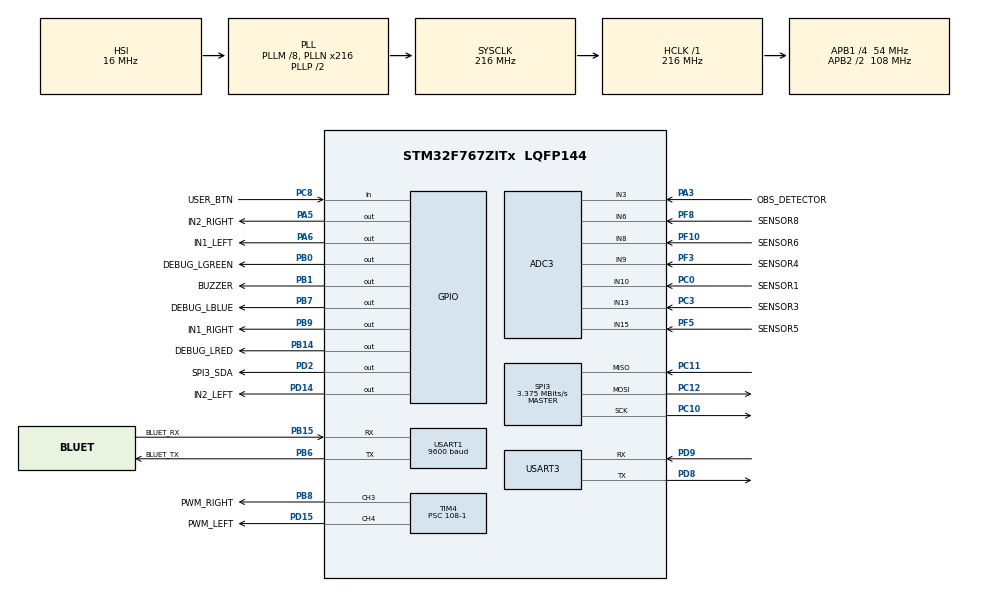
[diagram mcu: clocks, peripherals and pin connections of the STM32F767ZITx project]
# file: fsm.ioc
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Mcu.Family=STM32F7
NVIC.USART3_IRQn=true\:0\:0\:false\:false\:true\:true\:true
Dma.ADC3.0.FIFOMode=DMA_FIFOMODE_DISABLE
ADC2.ExternalTrigConv=ADC_SOFTWARE_START
Dma.ADC3.0.Priority=DMA_PRIORITY_LOW
RCC.CortexFreq_Value=216000000
SPI3.Direction=SPI_DIRECTION_2LINES
SPI3.VirtualType=VM_MASTER
ADC2.Channel-0\#ChannelRegularConversion=ADC_CHANNEL_3
ADC3.Channel-3\#ChannelRegularConversion=ADC_CHANNEL_15
NVIC.TIM6_DAC_IRQn=true\:0\:0\:true\:false\:true\:true\:true
USART1.BaudRate=9600
SPI3.NSSPMode=SPI_NSS_PULSE_DISABLE
PC10.Signal=SPI3_SCK
PC12.Signal=SPI3_MOSI
PB14.GPIO_Label=DEBUG_LRED
PC0.GPIO_Label=SENSOR1
PB0.GPIO_Label=DEBUG_LGREEN
PA6.GPIO_Label=IN1_LEFT
PB6.GPIO_Label=BLUET_TX
PB15.Signal=USART1_RX
ADC3.Channel-0\#ChannelRegularConversion=ADC_CHANNEL_10
PD9.Mode=Asynchronous
ADC3.Rank-2\#ChannelRegularConversion=3
RCC.SYSCLKSource=RCC_SYSCLKSOURCE_PLLCLK
ProjectManager.StackSize=0x400
USART3.VirtualMode-Asynchronous=VM_ASYNC
VP_TIM7_VS_ClockSourceINT.Mode=Enable_Timer
ADC3.SamplingTime-4\#ChannelRegularConversion=ADC_SAMPLETIME_112CYCLES
NVIC.ADC_IRQn=true\:0\:0\:false\:false\:true\:true\:true
ADC2.DMAContinuousRequests=ENABLE
RCC.HCLKFreq_Value=216000000
SH.ADCx_IN3.0=ADC3_IN3,IN3
SH.ADCx_IN3.1=ADC2_IN3,IN3
RCC.APB2TimFreq_Value=216000000
TIM3.Period=1800-1
PB6.Signal=USART1_TX
Dma.ADC3.0.Direction=DMA_PERIPH_TO_MEMORY
PB6.Mode=Asynchronous
PC3.Signal=ADCx_IN13
ADC3.ScanConvMode=ADC_SCAN_ENABLE
TIM7.Period=500-1
PD8.Signal=USART3_TX
Dma.ADC3.0.MemDataAlignment=DMA_MDATAALIGN_WORD
ADC2.EOCSelection=ADC_EOC_SINGLE_CONV
PF10.GPIO_Label=SENSOR6
RCC.AHBFreq_Value=216000000
SPI3.DataSize=SPI_DATASIZE_8BIT
TIM3.ClockDivision=TIM_CLOCKDIVISION_DIV1
ADC3.SamplingTime-1\#ChannelRegularConversion=ADC_SAMPLETIME_112CYCLES
RCC.HSE_VALUE=25000000
TIM4.Channel-PWM\ Generation3\ CH3=TIM_CHANNEL_3
ADC3.SamplingTime-2\#ChannelRegularConversion=ADC_SAMPLETIME_3CYCLES
Dma.ADC3.0.PeriphInc=DMA_PINC_DISABLE
Dma.ADC2.1.Instance=DMA2_Stream2
ADC3.SamplingTime-5\#ChannelRegularConversion=ADC_SAMPLETIME_112CYCLES
TIM3.Prescaler=60000-1
PB1.GPIO_Label=BUZZER
ADC3.ContinuousConvMode=ENABLE
Dma.ADC3.0.MemInc=DMA_MINC_ENABLE
PB7.Signal=GPIO_Output
PF8.Mode=IN6
Dma.ADC2.1.PeriphInc=DMA_PINC_DISABLE
TIM4.Period=100-0
TIM6.Period=100-1
ADC3.Channel-2\#ChannelRegularConversion=ADC_CHANNEL_9
PF3.Signal=ADC3_IN9
TIM7.TIM_MasterOutputTrigger=TIM_TRGO_UPDATE
ADC3.Rank-4\#ChannelRegularConversion=5
PB7.GPIO_Label=DEBUG_LBLUE
Mcu.Package=LQFP144
PB9.Signal=GPIO_Output
PB1.Signal=GPIO_Output
PA6.Signal=GPIO_Output
SPI3.Mode=SPI_MODE_MASTER
PF5.GPIO_Label=SENSOR5
ADC3.Rank-0\#ChannelRegularConversion=1
PF8.Signal=ADC3_IN6
ADC2.SamplingTime-0\#ChannelRegularConversion=ADC_SAMPLETIME_112CYCLES
TIM7.AutoReloadPreload=TIM_AUTORELOAD_PRELOAD_ENABLE
PC11.Mode=Full_Duplex_Master
NVIC.SPI3_IRQn=true\:0\:0\:false\:false\:true\:true\:true
PF5.Signal=ADC3_IN15
ADC3.DMAContinuousRequests=ENABLE
RCC.APB2CLKDivider=RCC_HCLK_DIV2
NVIC.DMA2_Stream2_IRQn=true\:0\:0\:false\:false\:true\:false\:true
Dma.Request1=ADC2
RCC.APB1TimFreq_Value=108000000
Dma.ADC3.0.Instance=DMA2_Stream1
PF10.Mode=IN8
ADC2.Rank-0\#ChannelRegularConversion=1
NVIC.USART1_IRQn=true\:0\:0\:false\:false\:true\:true\:true
TIM4.Channel-PWM\ Generation4\ CH4=TIM_CHANNEL_4
Dma.Request0=ADC3
PF3.GPIO_Label=SENSOR4
PD15.Signal=S_TIM4_CH4
Dma.ADC2.1.PeriphDataAlignment=DMA_PDATAALIGN_WORD
NVIC.TIM7_IRQn=true\:0\:0\:false\:false\:true\:true\:true
VP_TIM3_VS_ClockSourceINT.Mode=Internal
ADC2.ScanConvMode=ADC_SCAN_ENABLE
PA3.Signal=ADCx_IN3
ADC3.SamplingTime-3\#ChannelRegularConversion=ADC_SAMPLETIME_3CYCLES
SH.ADCx_IN13.0=ADC3_IN13,IN13
TIM4.AutoReloadPreload=TIM_AUTORELOAD_PRELOAD_ENABLE
PD15.GPIO_Label=PWM_LEFT
PF3.Mode=IN9
PB9.GPIO_Label=IN1_RIGHT
TIM3.AutoReloadPreload=TIM_AUTORELOAD_PRELOAD_ENABLE
SH.S_TIM4_CH4.0=TIM4_CH4,PWM Generation4 CH4
PC11.Signal=SPI3_MISO
PC8.Signal=GPIO_Input
TIM6.Prescaler=10800-1
PC10.Mode=Full_Duplex_Master
VP_TIM6_VS_ClockSourceINT.Mode=Enable_Timer
PD9.Signal=USART3_RX
NVIC.DMA2_Stream1_IRQn=true\:0\:0\:false\:false\:true\:false\:true
PC0.Signal=ADCx_IN10
ADC3.Rank-3\#ChannelRegularConversion=4
RCC.APB1CLKDivider=RCC_HCLK_DIV4
PF5.Mode=IN15
PF8.GPIO_Label=SENSOR8
PC8.GPIO_Label=USER_BTN
USART1.VirtualMode-Asynchronous=VM_ASYNC
TIM6.AutoReloadPreload=TIM_AUTORELOAD_PRELOAD_ENABLE
PB8.GPIO_Label=PWM_RIGHT
ADC3.SamplingTime-0\#ChannelRegularConversion=ADC_SAMPLETIME_112CYCLES
ADC2.ContinuousConvMode=ENABLE
ProjectManager.TargetToolchain=STM32CubeIDE
ADC3.Channel-4\#ChannelRegularConversion=ADC_CHANNEL_8
SH.S_TIM4_CH3.0=TIM4_CH3,PWM Generation3 CH3
RCC.USBFreq_Value=216000000
ADC3.NbrOfConversion=6
TIM4.Prescaler=108-1
Dma.ADC2.1.Mode=DMA_CIRCULAR
RCC.LSE_VALUE=32768
PD8.Mode=Asynchronous
PB14.Signal=GPIO_Output
PA5.Signal=GPIO_Output
Dma.ADC2.1.FIFOMode=DMA_FIFOMODE_DISABLE
PC12.Mode=Full_Duplex_Master
TIM7.Prescaler=10800-1
board=custom
RCC.VCOOutputFreq_Value=432000000
PB15.Mode=Asynchronous
NVIC.TIM3_IRQn=true\:0\:0\:false\:false\:true\:true\:true
RCC.APB2Freq_Value=108000000
ADC3.Channel-5\#ChannelRegularConversion=ADC_CHANNEL_6
SPI3.CalculateBaudRate=3.375 MBits/s
PB15.GPIO_Label=BLUET_RX
PF10.Signal=ADC3_IN8
SPI3.BaudRatePrescaler=SPI_BAUDRATEPRESCALER_16
TIM6.TIM_MasterOutputTrigger=TIM_TRGO_UPDATE
PD14.GPIO_Label=IN2_LEFT
Dma.ADC2.1.MemInc=DMA_MINC_ENABLE
ADC3.Rank-5\#ChannelRegularConversion=6
Mcu.Name=STM32F767ZITx
Dma.ADC3.0.PeriphDataAlignment=DMA_PDATAALIGN_WORD
ADC3.Channel-1\#ChannelRegularConversion=ADC_CHANNEL_13
PD14.Signal=GPIO_Output
PC8.GPIO_PuPd=GPIO_PULLDOWN
ADC3.Rank-1\#ChannelRegularConversion=2
RCC.SYSCLKFreq_VALUE=216000000
Dma.ADC2.1.Direction=DMA_PERIPH_TO_MEMORY
PA5.GPIO_Label=IN2_RIGHT
ADC2.NbrOfConversionFlag=1
SH.ADCx_IN10.1=ADC3_IN10,IN10
SH.ADCx_IN10.0=ADC1_IN10
ProjectManager.HeapSize=0x200
ADC3.EOCSelection=ADC_EOC_SINGLE_CONV
Dma.ADC3.0.Mode=DMA_CIRCULAR
RCC.HSI_VALUE=16000000
NVIC.PriorityGroup=NVIC_PRIORITYGROUP_4
Dma.ADC2.1.MemDataAlignment=DMA_MDATAALIGN_WORD
RCC.PLLM=8
RCC.PLLN=216
PB8.Signal=S_TIM4_CH3
PC3.GPIO_Label=SENSOR3
Dma.ADC2.1.Priority=DMA_PRIORITY_LOW
TIM3.TIM_MasterOutputTrigger=TIM_TRGO_UPDATE
PD2.Signal=GPIO_Output
NVIC.TIM4_IRQn=true\:0\:0\:false\:false\:true\:true\:true
RCC.APB1Freq_Value=54000000
ADC3.NbrOfConversionFlag=1
PB0.Signal=GPIO_Output
PD2.GPIO_Label=SPI3_SDA
PA3.GPIO_Label=OBS_DETECTOR

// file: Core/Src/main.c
/* USER CODE BEGIN Header */
/**
  ******************************************************************************
  * @file           : main.c
  * @brief          : Main program body
  ******************************************************************************
  * @attention
  *
  * <h2><center>&copy; Copyright (c) 2021 STMicroelectronics.
  * All rights reserved.</center></h2>
  *
  * This software component is licensed by ST under BSD 3-Clause license,
  * the "License"; You may not use this file except in compliance with the
  * License. You may obtain a copy of the License at:
  *                        opensource.org/licenses/BSD-3-Clause
  *
  ******************************************************************************
  */
/* USER CODE END Header */
#include "main.h"
#include "adc.h"
#include "dma.h"
#include "spi.h"
#include "tim.h"
#include "usart.h"
#include "gpio.h"

/* USER CODE BEGIN Includes */
#include "fsm.h"
#include "tests.h"

#include "rfid-rc522.h"
#include "timeout.h"
/* USER CODE END Includes */

void SystemClock_Config(void);

int main(void)
{

  /* MCU Configuration--------------------------------------------------------*/

  /* Reset of all peripherals, Initializes the Flash interface and the Systick. */
  HAL_Init();

  /* Configure the system clock */
  SystemClock_Config();

  /* Initialize all configured peripherals */
  MX_GPIO_Init();
  MX_DMA_Init();
  MX_SPI3_Init();
  MX_USART3_UART_Init();
  MX_TIM6_Init();
  MX_ADC3_Init();
  MX_TIM4_Init();
  MX_USART1_UART_Init();
  MX_TIM3_Init();
  MX_ADC2_Init();
  MX_TIM7_Init();

  /* Infinite loop */
  /* USER CODE BEGIN WHILE */

  // initialize FSM state and next state
  state = S_STOPPED;
  nstate = S_STOPPED;

  //while(1)
//	  test_lf_print_qtr();

  // enable RFID reader
  RFID_RC522_Init();
  // enable UART
  Rx_UART_init(&bluet_uart);
  // enable timeouts
  timeout_start();

  while (1)
  {
	  // execute state
	  fsm_func_ptr[state]();
	  // update current state
	  state = nstate;

    /* USER CODE END WHILE */

  }
}

void SystemClock_Config(void)
{
  RCC_OscInitTypeDef RCC_OscInitStruct = {0};
  RCC_ClkInitTypeDef RCC_ClkInitStruct = {0};
  RCC_PeriphCLKInitTypeDef PeriphClkInitStruct = {0};

  /** Configure the main internal regulator output voltage
  */
  __HAL_RCC_PWR_CLK_ENABLE();
  __HAL_PWR_VOLTAGESCALING_CONFIG(PWR_REGULATOR_VOLTAGE_SCALE1);
  /** Initializes the RCC Oscillators according to the specified parameters
  * in the RCC_OscInitTypeDef structure.
  */
  RCC_OscInitStruct.OscillatorType = RCC_OSCILLATORTYPE_HSI;
  RCC_OscInitStruct.HSIState = RCC_HSI_ON;
  RCC_OscInitStruct.HSICalibrationValue = RCC_HSICALIBRATION_DEFAULT;
  RCC_OscInitStruct.PLL.PLLState = RCC_PLL_ON;
  RCC_OscInitStruct.PLL.PLLSource = RCC_PLLSOURCE_HSI;
  RCC_OscInitStruct.PLL.PLLM = 8;
  RCC_OscInitStruct.PLL.PLLN = 216;
  RCC_OscInitStruct.PLL.PLLP = RCC_PLLP_DIV2;
  RCC_OscInitStruct.PLL.PLLQ = 2;
  if (HAL_RCC_OscConfig(&RCC_OscInitStruct) != HAL_OK)
  {
    Error_Handler();
  }
  /** Activate the Over-Drive mode
  */
  if (HAL_PWREx_EnableOverDrive() != HAL_OK)
  {
    Error_Handler();
  }
  /** Initializes the CPU, AHB and APB buses clocks
  */
  RCC_ClkInitStruct.ClockType = RCC_CLOCKTYPE_HCLK|RCC_CLOCKTYPE_SYSCLK
                              |RCC_CLOCKTYPE_PCLK1|RCC_CLOCKTYPE_PCLK2;
  RCC_ClkInitStruct.SYSCLKSource = RCC_SYSCLKSOURCE_PLLCLK;
  RCC_ClkInitStruct.AHBCLKDivider = RCC_SYSCLK_DIV1;
  RCC_ClkInitStruct.APB1CLKDivider = RCC_HCLK_DIV4;
  RCC_ClkInitStruct.APB2CLKDivider = RCC_HCLK_DIV2;

  if (HAL_RCC_ClockConfig(&RCC_ClkInitStruct, FLASH_LATENCY_7) != HAL_OK)
  {
    Error_Handler();
  }
  PeriphClkInitStruct.PeriphClockSelection = RCC_PERIPHCLK_USART1|RCC_PERIPHCLK_USART3;
  PeriphClkInitStruct.Usart1ClockSelection = RCC_USART1CLKSOURCE_PCLK2;
  PeriphClkInitStruct.Usart3ClockSelection = RCC_USART3CLKSOURCE_PCLK1;
  if (HAL_RCCEx_PeriphCLKConfig(&PeriphClkInitStruct) != HAL_OK)
  {
    Error_Handler();
  }
}

void Error_Handler(void)
{
  __disable_irq();
  while (1)
  {
  }
}

/************************ (C) COPYRIGHT STMicroelectronics *****END OF FILE****/
